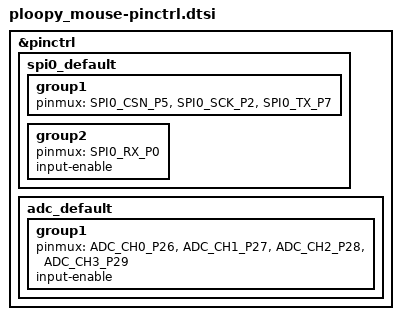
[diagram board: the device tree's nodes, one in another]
/*
 * Copyright (c) 2025, George Norton
 * SPDX-License-Identifier: MIT
 */

#include <dt-bindings/pinctrl/rpi-pico-rp2040-pinctrl.h>

&pinctrl {
    spi0_default: spi0_default {
        group1 {
            pinmux = <SPI0_CSN_P5>, <SPI0_SCK_P2>, <SPI0_TX_P7>;
        };
        group2 {
            pinmux = <SPI0_RX_P0>;
            input-enable;
        };
    };

    adc_default: adc_default {
        group1 {
            pinmux = <ADC_CH0_P26>, <ADC_CH1_P27>, <ADC_CH2_P28>, <ADC_CH3_P29>;
            input-enable;
        };
    };

};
